# nrf7120E_enga_application register map
Vendor: Nordic Semiconductor; Series: nrf71; File version: 1
CPU: CM33 r0p4, little endian, MPU, FPU, 3 interrupt priority bits, 270 interrupts, 4 SAU regions
Registers are 32-bit, read-write, reset 0x0 unless marked. A register's access mark holds for its fields unless they carry their own. Offsets are from the block's base; [hi:lo] are bit positions; lines under a group give offsets from that group; {n}, {i} and the like mark numbered series; 'fields as' and 'values as' point back to an identical list.

## GLOBAL_PPIB00_NS — PPIB APB registers 0
Base 0x40044000
Same registers: GLOBAL_PPIB01_NS 0x40045000, GLOBAL_PPIB10_NS 0x40083000, GLOBAL_PPIB11_NS 0x40084000, GLOBAL_PPIB20_NS 0x400C3000, GLOBAL_PPIB21_NS 0x400C4000, GLOBAL_PPIB22_NS 0x400C5000, GLOBAL_PPIB30_NS 0x40103000, GLOBAL_PPIB00_S 0x50044000, GLOBAL_PPIB01_S 0x50045000, GLOBAL_PPIB10_S 0x50083000, GLOBAL_PPIB11_S 0x50084000, GLOBAL_PPIB20_S 0x500C3000, GLOBAL_PPIB21_S 0x500C4000, GLOBAL_PPIB22_S 0x500C5000, GLOBAL_PPIB30_S 0x50103000
{0x0+4i} TASKS_SEND[{i}] (i=0..31) wo — Description collection: This task is unused, but the PPIB provides the SUBSCRIBE task to connect SEND [n] task.
  [0] TASKS_SEND — This task is unused, but the PPIB provides the SUBSCRIBE task to connect SEND [n] task.
    1=Trigger task
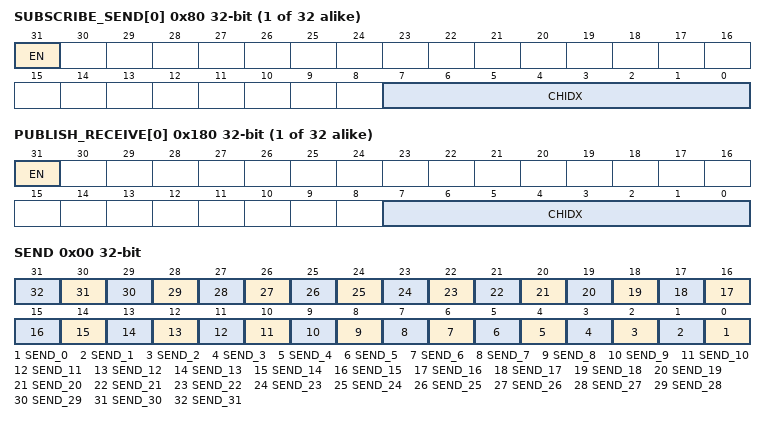
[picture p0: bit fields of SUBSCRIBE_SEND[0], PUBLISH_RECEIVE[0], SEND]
{0x80+4i} SUBSCRIBE_SEND[{i}] (i=0..31) — Description collection: Subscribe configuration for task SEND[n]
  [31] EN
    0=Disabled (Disable subscription); 1=Enabled (Enable subscription)
  [7:0] CHIDX — DPPI channel that task SEND[n] will subscribe to
{0x100+4i} EVENTS_RECEIVE[{i}] (i=0..31) — Description collection: This event is unused, but the PPIB provides the PUBLISH event to connect RECEIVE [n] event.
  [0] EVENTS_RECEIVE — This event is unused, but the PPIB provides the PUBLISH event to connect RECEIVE [n] event.
    0=NotGenerated (Event not generated); 1=Generated (Event generated)
{0x180+4i} PUBLISH_RECEIVE[{i}] (i=0..31) — Description collection: Publish configuration for event RECEIVE[n]
  [31] EN
    0=Disabled (Disable publishing); 1=Enabled (Enable publishing)
  [7:0] CHIDX — DPPI channel that event RECEIVE[n] will publish to
0x400 OVERFLOW group — Unspecified
  0x00 SEND — The task overflow for SEND tasks using SUBSCRIBE_SEND. Write 0 to clear.
    [all] fields
      1=Overflow (Task overflow is happened.); 0=NoOverflow (Task overflow is not happened.)
    [n] SEND_{n} (n=0..31) — The status for tasks overflow at SUBSCRIBE_SEND[{n}].

## GLOBAL_ECB00_NS — AES ECB Mode Encryption 0
Base 0x4004B000
Same registers: GLOBAL_ECB00_S 0x5004B000
0x00 TASKS_START wo — Start ECB block encrypt
  [0] TASKS_START
    1=Trigger task
0x04 TASKS_STOP wo — Abort a possible executing ECB operation
  [0] TASKS_STOP
    1=Trigger task
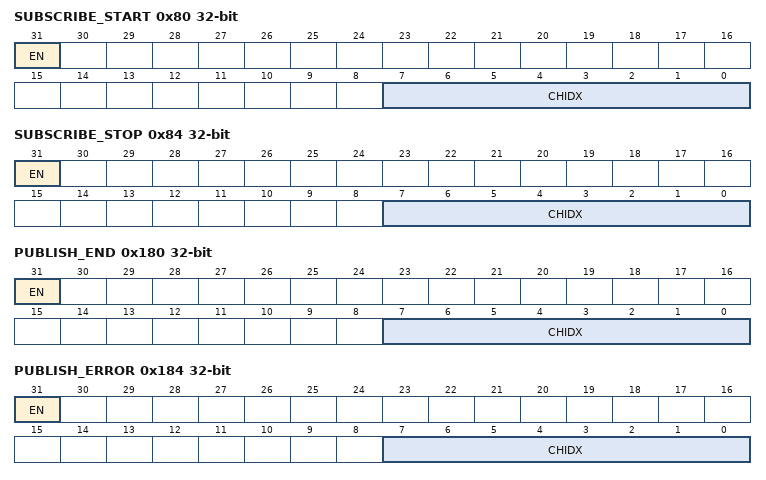
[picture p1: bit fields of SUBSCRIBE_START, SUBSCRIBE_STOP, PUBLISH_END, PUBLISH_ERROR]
0x80 SUBSCRIBE_START — Subscribe configuration for task START
  [31] EN
    0=Disabled (Disable subscription); 1=Enabled (Enable subscription)
  [7:0] CHIDX — DPPI channel that task START will subscribe to
0x84 SUBSCRIBE_STOP — Subscribe configuration for task STOP
  [31] EN
    values as SUBSCRIBE_START.EN
  [7:0] CHIDX — DPPI channel that task STOP will subscribe to
0x100 EVENTS_END — ECB block encrypt complete
  [0] EVENTS_END
    0=NotGenerated (Event not generated); 1=Generated (Event generated)
0x104 EVENTS_ERROR — ECB block encrypt aborted because of a STOP task or due to an error
  [0] EVENTS_ERROR
    values as EVENTS_END.EVENTS_END
0x180 PUBLISH_END — Publish configuration for event END
  [31] EN
    0=Disabled (Disable publishing); 1=Enabled (Enable publishing)
  [7:0] CHIDX — DPPI channel that event END will publish to
0x184 PUBLISH_ERROR — Publish configuration for event ERROR
  [31] EN
    values as PUBLISH_END.EN
  [7:0] CHIDX — DPPI channel that event ERROR will publish to
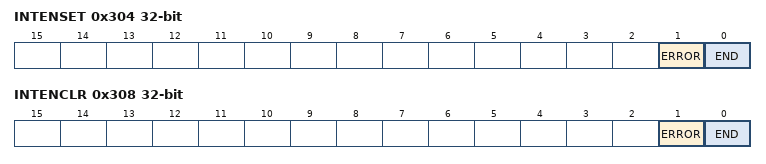
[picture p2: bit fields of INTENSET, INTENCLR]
0x304 INTENSET — Enable interrupt
  [1] ERROR write-1-sets — Write '1' to enable interrupt for event ERROR
    on read: 0=Disabled (Read: Disabled); 1=Enabled (Read: Enabled) | on write: 1=Set (Enable)
  [0] END write-1-sets — Write '1' to enable interrupt for event END
    values as ERROR
0x308 INTENCLR — Disable interrupt
  [1] ERROR write-1-clears — Write '1' to disable interrupt for event ERROR
    on read: 0=Disabled (Read: Disabled); 1=Enabled (Read: Enabled) | on write: 1=Clear (Disable)
  [0] END write-1-clears — Write '1' to disable interrupt for event END
    values as ERROR
0x400 ERRORSTATUS ro
  [2:0] ERRORSTATUS — Error status when the ERROR event is generated
    0=No errors have occurred; 1=PrematureInptrEnd (End of INPTR job list before data structure was read.); 2=PrematureOutptrEnd (End of OUTPTR job list before data structure was read.); 3=EncryptionTooSlow (Deprecated enumerator - Encryption aborted due to higher priority peripheral requesting or using the AES module.); 3=Aborted (Encryption aborted due to higher priority peripheral requesting or using the AES module.); 4=DmaError (Bus error during DMA access.)
0x510 KEY group — Unspecified
  {0x0+4j} VALUE[{j}] (j=0..3) wo — Description collection: 128-bit AES key
    [31:0] VALUE — AES 128-bit key value, bits (32*(n+1))-1 : (32*n)
0x530 IN group — IN EasyDMA channel
  0x00 PTR — Input pointer
    [31:0] PTR — Points to a job list containing unencrypted ECB data structure
0x538 OUT group — OUT EasyDMA channel
  0x00 PTR — Output pointer Points to a job list containing encrypted ECB data structure
    [31:0] PTR — Output pointer
0x53C CSAA group — Channel sounding access address scoring algorithm
  0x00 REFLECTOR ro — Selected Channel Sounding Access Address used in the CS SYNC from Reflector to Initiator
    [31:0] PN
  0x04 INITIATOR ro — Selected Channel Sounding Access Address used in the CS SYNC from Initiator to Reflector
    [31:0] PN
  0x08 MODE — Operation modes
    [0] BITREVERSE — Reverse the endianness on bit level for the ECB output, INITIATOR, and REFLECTOR registers
      0=Default endianness; 1=Reversed endianness
